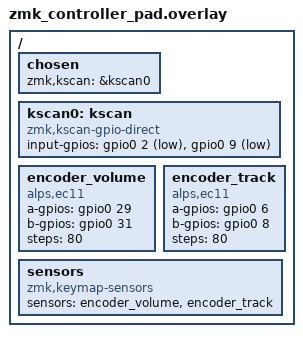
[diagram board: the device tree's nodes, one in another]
#include <dt-bindings/gpio/gpio.h>

/ {
    chosen {
        zmk,kscan = &kscan0;
    };

    kscan0: kscan {
        compatible = "zmk,kscan-gpio-direct";
        input-gpios
            = <&gpio0 2 (GPIO_ACTIVE_LOW | GPIO_PULL_UP)>
            , <&gpio0 9 (GPIO_ACTIVE_LOW | GPIO_PULL_UP)>
            ;
    };

    encoder_volume: encoder_volume {
        compatible = "alps,ec11";
        a-gpios = <&gpio0 29 (GPIO_ACTIVE_HIGH | GPIO_PULL_UP)>;
        b-gpios = <&gpio0 31 (GPIO_ACTIVE_HIGH | GPIO_PULL_UP)>;
        steps = <80>;
        status = "okay";
    };

    encoder_track: encoder_track {
        compatible = "alps,ec11";
        a-gpios = <&gpio0 6 (GPIO_ACTIVE_HIGH | GPIO_PULL_UP)>;
        b-gpios = <&gpio0 8 (GPIO_ACTIVE_HIGH | GPIO_PULL_UP)>;
        steps = <80>;
        status = "okay";
    };

    sensors {
        compatible = "zmk,keymap-sensors";
        sensors = <&encoder_volume &encoder_track>;
    };
};
